# PIC32CX1025MTSH128 register map
Vendor: Microchip Technology; Series: PIC32CXMTSH; File version: 0
CPU: CM4 r0p1, selectable endian, MPU, FPU, 4 interrupt priority bits
Registers are 32-bit, read-write, reset 0x0 unless marked. A register's access mark holds for its fields unless they carry their own. Offsets are from the block's base; [hi:lo] are bit positions; {n}, {i} and the like mark numbered series.

## GPBR — General Purpose Backup Registers
Base 0x40053060; register names take the prefix GPBR_
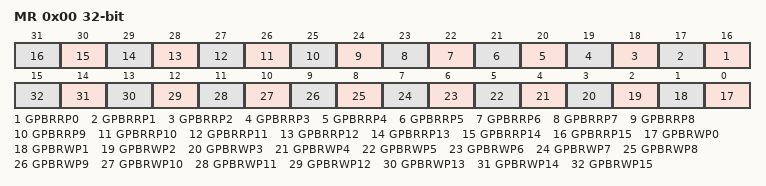
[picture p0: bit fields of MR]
0x00 MR — GPBR Mode Register
  [n+16] GPBRRP{n} (n=0..15) — GPBRx Read Protection
  [n] GPBRWP{n} (n=0..15) — GPBRx Write Protection
{0x8+4i} SYS_GPBR[{i}] (i=0..23) — General Purpose Backup Register
  [31:0] GPBR_VALUE — Value of SYS_GPBRx

## IPC0 — Inter-processor Communication
Base 0x4002C000; register names take the prefix IPC_
Same registers: IPC1 0x48014000
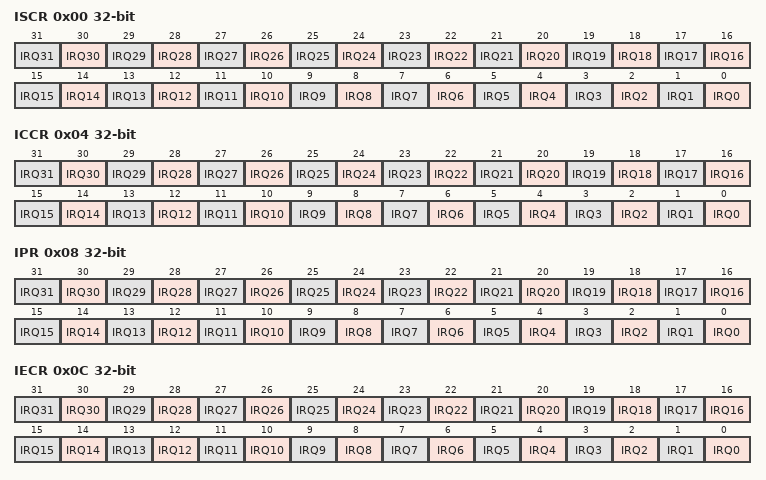
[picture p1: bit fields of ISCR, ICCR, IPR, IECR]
0x00 ISCR wo — Interrupt Set Command Register
  [n] IRQ{n} (n=0..31) — Interrupt Set
0x04 ICCR wo — Interrupt Clear Command Register
  [n] IRQ{n} (n=0..31) — Interrupt Clear
0x08 IPR ro — Interrupt Pending Register
  [n] IRQ{n} (n=0..31) — Interrupt Pending
0x0C IECR wo — Interrupt Enable Command Register
  [n] IRQ{n} (n=0..31) — Interrupt Enable
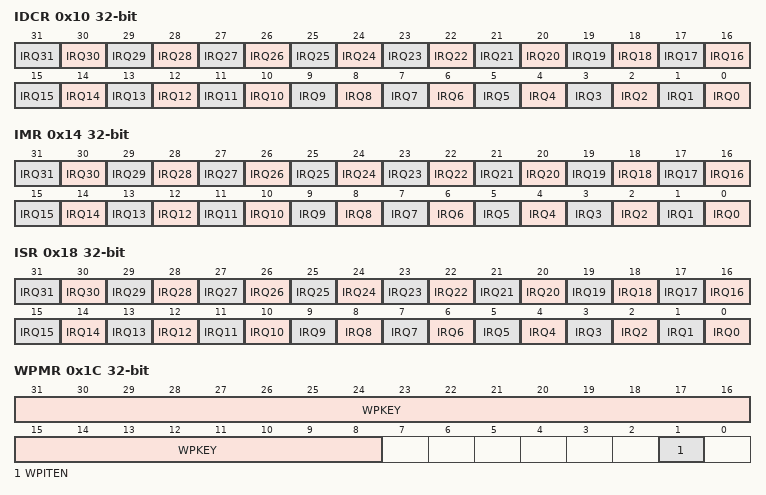
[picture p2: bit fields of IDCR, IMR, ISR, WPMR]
0x10 IDCR wo — Interrupt Disable Command Register
  [n] IRQ{n} (n=0..31) — Interrupt Disable
0x14 IMR ro — Interrupt Mask Register
  [n] IRQ{n} (n=0..31) — Interrupt Mask
0x18 ISR ro — Interrupt Status Register
  [n] IRQ{n} (n=0..31) — Current Interrupt Identifier
0x1C WPMR — Write Protection Mode Register
  [31:8] WPKEY — Write Protection Key
    0x495043=PASSWD (Writing any other value in this field aborts the write operation of the WPEN bit. Always reads as 0.)
  [1] WPITEN — Write Protection Interrupt Enable

## RSTC — Reset Controller
Base 0x40053000; register names take the prefix RSTC_
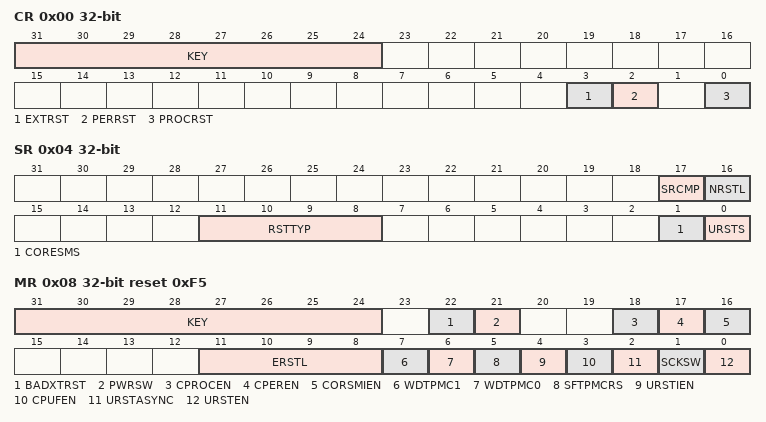
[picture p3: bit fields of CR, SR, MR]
0x00 CR wo — Control Register
  [31:24] KEY — System Reset Key
    165=PASSWD (Writing any other value in this field aborts the write operation.)
  [3] EXTRST — External Reset
  [2] PERRST — Peripheral Reset
  [0] PROCRST — Processor Reset
0x04 SR ro — Status Register
  [17] SRCMP — Software Reset Command in Progress
  [16] NRSTL — NRST Pin Level
  [11:8] RSTTYP — Reset Type
    0=GENERAL_RST (First power-up reset, Core and VDD3V3 Supply Monitor if not a PORVDD3V3 reset); 1=BACKUP_RST (VDDCORE reset. Wake-up from Backup mode); 2=WDT0_RST (Watchdog 0 fault occurred); 3=SOFT_RST (Processor reset required by the software); 4=USER_RST (NRST pin detected low); 5=CORE_SM_RST (Core Supply Monitor reset); 6=CPU_FAIL_RST (CPU clock failure detection occurred); 7=SLCK_XTAL_RST (32.768 kHz crystal failure detection fault occurred); 9=WDT1_RST (Watchdog 1 fault occurred); 10=PORVDD3V3_RST (VDD3V3 PORVDD3V3 reset occurred)
  [1] CORESMS — VDDCORE Supply Monitor Reset Flag Status (cleared on read)
  [0] URSTS — User Reset Status (cleared on read)
0x08 MR reset 0xF5 — Mode Register
  [31:24] KEY — Write Access Password
    165=PASSWD (Writing any other value in this field aborts the write operation. Always reads as 0.)
  [22] BADXTRST — Bad XTAL Fail Reset
  [21] PWRSW — Backup Area Power Switch Control
    0=VDD3V3 (VDDBU is supplied by VDD3V3); 1=VBAT (VDDBU is supplied by VBAT)
  [18] CPROCEN — Coprocessor (Second Processor) Enable
  [17] CPEREN — Coprocessor Peripheral Enable
  [16] CORSMIEN — VDDCORE Supply Monitor Interrupt Enable
  [11:8] ERSTL — External Reset Length
  [7] WDTPMC1 — WDT1 PMC Reset
  [6] WDTPMC0 — WDT0 PMC Reset
  [5] SFTPMCRS — Software PMC Reset
  [4] URSTIEN — User Reset Interrupt Enable
  [3] CPUFEN — CPU Fail Enable
  [2] URSTASYNC — User Reset Asynchronous Control
  [1] SCKSW — Slow Clock Switching
  [0] URSTEN — User Reset Enable

## RTT — Real-time Timer
Base 0x40053020; register names take the prefix RTT_
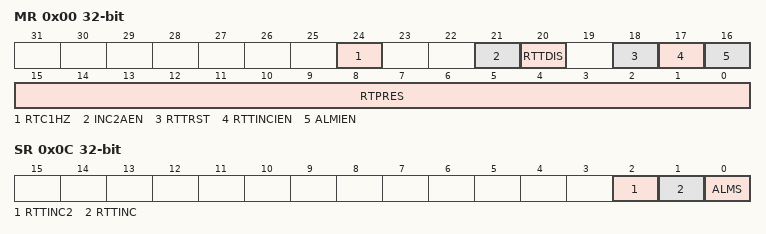
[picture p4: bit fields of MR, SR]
0x00 MR — Mode Register
  [24] RTC1HZ — Real-Time Clock 1Hz Clock Selection
  [21] INC2AEN — RTTINC2 Alarm and Interrupt Enable
  [20] RTTDIS — Real-time Timer Disable
  [18] RTTRST — Real-time Timer Restart
  [17] RTTINCIEN — Real-time Timer Increment Interrupt Enable
  [16] ALMIEN — Alarm Interrupt Enable
  [15:0] RTPRES — Real-time Timer Prescaler Value
0x04 AR — Alarm Register
  [31:0] ALMV — Alarm Value
0x08 VR ro — Value Register
  [31:0] CRTV — Current Real-time Value
0x0C SR ro — Status Register
  [2] RTTINC2 — Predefined Number of Prescaler Roll-overs Status (cleared on read)
  [1] RTTINC — Prescaler Roll-over Status (cleared on read)
  [0] ALMS — Real-time Alarm Status (cleared on read)
0x10 MODR — Modulo Selection Register
  [2:0] SELINC2 — Selection of the 32-bit Counter Modulo to generate RTTINC2 Flag
    0=NO_RTTINC2 (The RTTINC2 flag never rises); 1=MOD64 (The RTTINC2 flag is set when CRTV modulo 64 equals 0); 2=MOD128 (The RTTINC2 flag is set when CRTV modulo 128 equals 0); 3=MOD256 (The RTTINC2 flag is set when CRTV modulo 256 equals 0); 4=MOD512 (The RTTINC2 flag is set when CRTV modulo 512 equals 0); 5=MOD1024 (The RTTINC2 flag is set when CRTV modulo 1024 equals 0. Example: If RTPRES=32 then RTTINC2 flag rises once per second if the slow clock is 32.768 kHz.); 6=MOD2048 (The RTTINC2 flag is set when CRTV modulo 2048 equals 0); 7=MOD4096 (The RTTINC2 flag is set when CRTV modulo 4096 equals 0)
